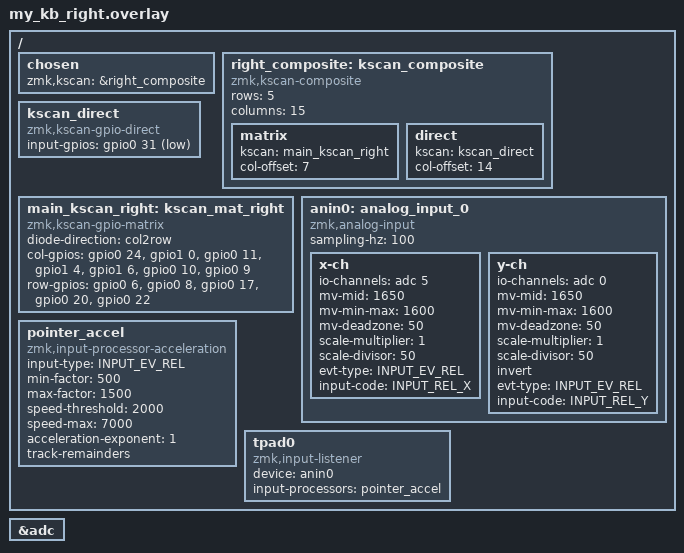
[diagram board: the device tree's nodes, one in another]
#include "my_kb.dtsi"
#include <dt-bindings/zmk/pointing.h>
#include <behaviors/input_gestures_accel.dtsi>

/ {
    // 右手（Master）起動時は、単体のkscanではなく複合kscan（right_composite）を使用する
    chosen {
        zmk,kscan = &right_composite;
    };

    right_composite: kscan_composite {
        compatible = "zmk,kscan-composite";
        rows = <5>;
        columns = <15>; 

        // ⭕ 共用の &main_kscan ではなく、右手専用の &main_kscan_right を指定する！
        matrix {
            kscan = <&main_kscan_right>;
            col-offset = <7>; 
        };

        direct {
            kscan = <&kscan_direct>;
            col-offset = <14>; 
        };
    };

    kscan_direct: kscan_direct {
        compatible = "zmk,kscan-gpio-direct";
        input-gpios = <&gpio0 15 (GPIO_ACTIVE_LOW | GPIO_PULL_UP)>; 
    };

    // ⭕ 右手専用のマトリックスノードを新設（ラベル名を main_kscan_right に変更）
    main_kscan_right: kscan_mat_right {
        compatible = "zmk,kscan-gpio-matrix";
        diode-direction = "col2row";

        col-gpios
            = <&gpio0 24 GPIO_ACTIVE_HIGH> /* これが内部列7（Yの列）として独立して正しく認識されます！ */
            , <&gpio1  0 GPIO_ACTIVE_HIGH> 
            , <&gpio0 11 GPIO_ACTIVE_HIGH> 
            , <&gpio1  4 GPIO_ACTIVE_HIGH> 
            , <&gpio1  6 GPIO_ACTIVE_HIGH> 
            , <&gpio0 10 GPIO_ACTIVE_HIGH> 
            , <&gpio0  9 GPIO_ACTIVE_HIGH> 
            ;

        row-gpios
            = <&gpio0  6 (GPIO_ACTIVE_HIGH | GPIO_PULL_DOWN)> 
            , <&gpio0  8 (GPIO_ACTIVE_HIGH | GPIO_PULL_DOWN)> 
            , <&gpio0 17 (GPIO_ACTIVE_HIGH | GPIO_PULL_DOWN)> 
            , <&gpio0 20 (GPIO_ACTIVE_HIGH | GPIO_PULL_DOWN)> 
            , <&gpio0 22 (GPIO_ACTIVE_HIGH | GPIO_PULL_DOWN)> 
            ;
    };

    // 右手直結のJoy-Con用ダイレクトキースキャン定義
    kscan_direct: kscan_direct {
        compatible = "zmk,kscan-gpio-direct";
    };
    anin0: analog_input_0 {
        compatible = "zmk,analog-input";
        sampling-hz = <100>;
        x-ch {
            io-channels = <&adc 5>;
            mv-mid = <1650>;
            mv-min-max = <1600>;
            mv-deadzone = <50>;
            scale-multiplier = <1>;
            scale-divisor = <50>;
            evt-type = <INPUT_EV_REL>;
            input-code = <INPUT_REL_X>;
        };
        y-ch {
            io-channels = <&adc 0>;
            mv-mid = <1650>;
            mv-min-max = <1600>;
            mv-deadzone = <50>;
            scale-multiplier = <1>;
            scale-divisor = <50>;
            invert;
            evt-type = <INPUT_EV_REL>;
            input-code = <INPUT_REL_Y>;
        };
    };
    // マウスポインタのアナログパッド
    pointer_accel: pointer_accel {
        compatible = "zmk,input-processor-acceleration";
        #input-processor-cells = <0>;
        input-type = <INPUT_EV_REL>; 
        min-factor = <500>;
        max-factor = <1500>;
        speed-threshold = <2000>;
        speed-max = <7000>;
        acceleration-exponent = <1>;
        track-remainders;
    };

    tpad0: tpad0 {
        compatible = "zmk,input-listener";
        status = "okay";
        device = <&anin0>;
        input-processors = <&pointer_accel>;
    };
};


/* 右手のアナログパッド用クリックピンをここで参照定義 */
&kscan_direct {
    input-gpios = <&gpio0 31 (GPIO_ACTIVE_LOW | GPIO_PULL_UP)>;
};

&adc {
    status = "okay";
};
